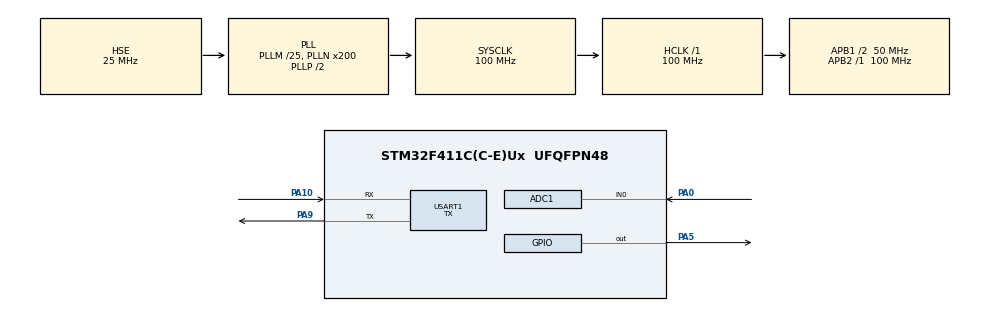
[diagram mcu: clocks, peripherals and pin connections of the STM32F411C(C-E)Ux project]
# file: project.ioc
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ADC1.Channel-0\#ChannelRegularConversion=ADC_CHANNEL_0
ADC1.ExternalTrigConv=ADC_EXTERNALTRIGCONV_T2_TRGO
ADC1.NbrOfConversion=1
ADC1.NbrOfConversionFlag=1
ADC1.Rank-0\#ChannelRegularConversion=1
ADC1.SamplingTime-0\#ChannelRegularConversion=ADC_SAMPLETIME_84CYCLES
ADC1.master=1
Dma.ADC1.0.Direction=DMA_PERIPH_TO_MEMORY
Dma.ADC1.0.FIFOMode=DMA_FIFOMODE_DISABLE
Dma.ADC1.0.Instance=DMA2_Stream0
Dma.ADC1.0.MemDataAlignment=DMA_MDATAALIGN_HALFWORD
Dma.ADC1.0.MemInc=DMA_MINC_ENABLE
Dma.ADC1.0.Mode=DMA_CIRCULAR
Dma.ADC1.0.PeriphDataAlignment=DMA_PDATAALIGN_HALFWORD
Dma.ADC1.0.PeriphInc=DMA_PINC_DISABLE
Dma.ADC1.0.Priority=DMA_PRIORITY_LOW
Dma.Request0=ADC1
Mcu.Family=STM32F4
Mcu.Name=STM32F411C(C-E)Ux
Mcu.Package=UFQFPN48
NVIC.DMA2_Stream0_IRQn=true\:0\:0\:false\:false\:true\:false\:true\:true
NVIC.PriorityGroup=NVIC_PRIORITYGROUP_4
PA0-WKUP.Signal=ADCx_IN0
PA10.Mode=Asynchronous
PA10.Signal=USART1_RX
PA5.Signal=GPIO_Output
PA9.Mode=Asynchronous
PA9.Signal=USART1_TX
PH0\ -\ OSC_IN.Mode=HSE-External-Oscillator
PH0\ -\ OSC_IN.Signal=RCC_OSC_IN
PH1\ -\ OSC_OUT.Mode=HSE-External-Oscillator
PH1\ -\ OSC_OUT.Signal=RCC_OSC_OUT
ProjectManager.HeapSize=0x200
ProjectManager.StackSize=0x400
ProjectManager.TargetToolchain=Makefile
RCC.48MHZClocksFreq_Value=50000000
RCC.AHBFreq_Value=100000000
RCC.APB1CLKDivider=RCC_HCLK_DIV2
RCC.APB1Freq_Value=50000000
RCC.APB1TimFreq_Value=100000000
RCC.APB2Freq_Value=100000000
RCC.APB2TimFreq_Value=100000000
RCC.CortexFreq_Value=100000000
RCC.HCLKFreq_Value=100000000
RCC.HSE_VALUE=25000000
RCC.HSI_VALUE=16000000
RCC.LSE_VALUE=32768
RCC.PLLM=25
RCC.PLLN=200
RCC.PLLSourceVirtual=RCC_PLLSOURCE_HSE
RCC.SYSCLKFreq_VALUE=100000000
RCC.SYSCLKSource=RCC_SYSCLKSOURCE_PLLCLK
RCC.VCOOutputFreq_Value=200000000
SH.ADCx_IN0.0=ADC1_IN0,IN0
TIM2.Prescaler=9999
TIM2.TIM_MasterOutputTrigger=TIM_TRGO_UPDATE
USART1.Mode=MODE_TX
USART1.VirtualMode=VM_ASYNC
VP_TIM2_VS_ClockSourceINT.Mode=Internal
board=custom

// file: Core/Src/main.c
/* USER CODE BEGIN Header */
/**
  ******************************************************************************
  * @file           : main.c
  * @brief          : Main program body
  ******************************************************************************
  * @attention
  *
  * Copyright (c) 2026 STMicroelectronics.
  * All rights reserved.
  *
  * This software is licensed under terms that can be found in the LICENSE file
  * in the root directory of this software component.
  * If no LICENSE file comes with this software, it is provided AS-IS.
  *
  ******************************************************************************
  */
/* USER CODE END Header */
#include "main.h"
#include "adc.h"
#include "dma.h"
#include "tim.h"
#include "usart.h"
#include "gpio.h"

/* USER CODE BEGIN Includes */
#include <stdio.h>
#include <string.h>
/* USER CODE END Includes */

/* USER CODE BEGIN PV */

uint16_t adc_buffer;          // single ADC sample via DMA
char uart_tx_buf[32];         // UART transmit buffer

/* USER CODE END PV */

void SystemClock_Config(void);

int main(void)
{

  /* MCU Configuration--------------------------------------------------------*/

  /* Reset of all peripherals, Initializes the Flash interface and the Systick. */
  HAL_Init();

  /* Configure the system clock */
  SystemClock_Config();

  /* Initialize all configured peripherals */
  MX_GPIO_Init();
  MX_DMA_Init();
  MX_ADC1_Init();
  MX_TIM2_Init();
  MX_USART1_UART_Init();
  /* USER CODE BEGIN 2 */

  /* Start ADC in DMA mode */
  HAL_ADC_Start_DMA(&hadc1, (uint32_t *)&adc_buffer, 1);

  /* Start timer (this triggers ADC at 100 Hz) */
  HAL_TIM_Base_Start(&htim2);

  /* USER CODE END 2 */

  /* Infinite loop */
  while (1)
  {

  }
}

void SystemClock_Config(void)
{
  RCC_OscInitTypeDef RCC_OscInitStruct = {0};
  RCC_ClkInitTypeDef RCC_ClkInitStruct = {0};

  /** Configure the main internal regulator output voltage
  */
  __HAL_RCC_PWR_CLK_ENABLE();
  __HAL_PWR_VOLTAGESCALING_CONFIG(PWR_REGULATOR_VOLTAGE_SCALE1);

  /** Initializes the RCC Oscillators according to the specified parameters
  * in the RCC_OscInitTypeDef structure.
  */
  RCC_OscInitStruct.OscillatorType = RCC_OSCILLATORTYPE_HSE;
  RCC_OscInitStruct.HSEState = RCC_HSE_ON;
  RCC_OscInitStruct.PLL.PLLState = RCC_PLL_ON;
  RCC_OscInitStruct.PLL.PLLSource = RCC_PLLSOURCE_HSE;
  RCC_OscInitStruct.PLL.PLLM = 25;
  RCC_OscInitStruct.PLL.PLLN = 200;
  RCC_OscInitStruct.PLL.PLLP = RCC_PLLP_DIV2;
  RCC_OscInitStruct.PLL.PLLQ = 4;
  if (HAL_RCC_OscConfig(&RCC_OscInitStruct) != HAL_OK)
  {
    Error_Handler();
  }

  /** Initializes the CPU, AHB and APB buses clocks
  */
  RCC_ClkInitStruct.ClockType = RCC_CLOCKTYPE_HCLK|RCC_CLOCKTYPE_SYSCLK
                              |RCC_CLOCKTYPE_PCLK1|RCC_CLOCKTYPE_PCLK2;
  RCC_ClkInitStruct.SYSCLKSource = RCC_SYSCLKSOURCE_PLLCLK;
  RCC_ClkInitStruct.AHBCLKDivider = RCC_SYSCLK_DIV1;
  RCC_ClkInitStruct.APB1CLKDivider = RCC_HCLK_DIV2;
  RCC_ClkInitStruct.APB2CLKDivider = RCC_HCLK_DIV1;

  if (HAL_RCC_ClockConfig(&RCC_ClkInitStruct, FLASH_LATENCY_3) != HAL_OK)
  {
    Error_Handler();
  }
}

/* USER CODE BEGIN 4 */

void HAL_ADC_ConvCpltCallback(ADC_HandleTypeDef *hadc)
{
    if (hadc->Instance == ADC1)
    {
        int len = snprintf(uart_tx_buf, sizeof(uart_tx_buf),
                           "ADC: %u\r\n", adc_buffer);

        HAL_UART_Transmit(&huart1,
                  (uint8_t *)uart_tx_buf,
                  len,
                  10);   // 10 ms is enough at 115200

    }
}

/* USER CODE END 4 */

void Error_Handler(void)
{
  __disable_irq();
  while (1)
  {
  }
}
